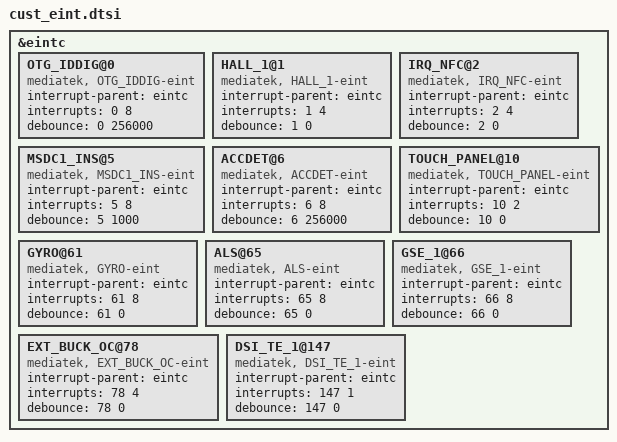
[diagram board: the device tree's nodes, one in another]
/*
 * Generated by MTK SP Drv_CodeGen Version 03.13.6  for MT6735. Copyright MediaTek Inc. (C) 2013.
 * Wed May 10 16:57:40 2017
 * Do Not Modify the File.
 */

/*************************
 * EINT DTSI File
*************************/

&eintc {
	OTG_IDDIG@0 {
		compatible = "mediatek, OTG_IDDIG-eint";
		interrupt-parent = <&eintc>;
		interrupts = <0 8>;
		debounce = <0 256000>;
	};

	HALL_1@1 {
		compatible = "mediatek, HALL_1-eint";
		interrupt-parent = <&eintc>;
		interrupts = <1 4>;
		debounce = <1 0>;
	};

	IRQ_NFC@2 {
		compatible = "mediatek, IRQ_NFC-eint";
		interrupt-parent = <&eintc>;
		interrupts = <2 4>;
		debounce = <2 0>;
	};

	MSDC1_INS@5 {
		compatible = "mediatek, MSDC1_INS-eint";
		interrupt-parent = <&eintc>;
		interrupts = <5 8>;
		debounce = <5 1000>;
	};

	ACCDET@6 {
		compatible = "mediatek, ACCDET-eint";
		interrupt-parent = <&eintc>;
		interrupts = <6 8>;
		debounce = <6 256000>;
	};

	TOUCH_PANEL@10 {
		compatible = "mediatek, TOUCH_PANEL-eint";
		interrupt-parent = <&eintc>;
		interrupts = <10 2>;
		debounce = <10 0>;
	};

	GYRO@61 {
		compatible = "mediatek, GYRO-eint";
		interrupt-parent = <&eintc>;
		interrupts = <61 8>;
		debounce = <61 0>;
	};

	ALS@65 {
		compatible = "mediatek, ALS-eint";
		interrupt-parent = <&eintc>;
		interrupts = <65 8>;
		debounce = <65 0>;
	};

	GSE_1@66 {
		compatible = "mediatek, GSE_1-eint";
		interrupt-parent = <&eintc>;
		interrupts = <66 8>;
		debounce = <66 0>;
	};

	EXT_BUCK_OC@78 {
		compatible = "mediatek, EXT_BUCK_OC-eint";
		interrupt-parent = <&eintc>;
		interrupts = <78 4>;
		debounce = <78 0>;
	};

	DSI_TE_1@147 {
		compatible = "mediatek, DSI_TE_1-eint";
		interrupt-parent = <&eintc>;
		interrupts = <147 1>;
		debounce = <147 0>;
	};

};
